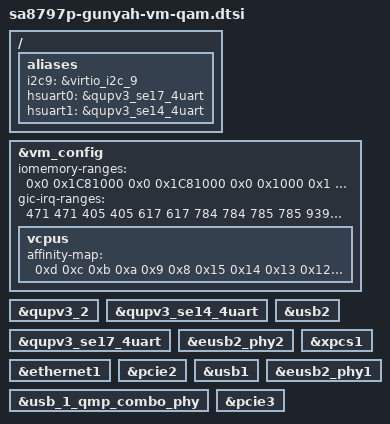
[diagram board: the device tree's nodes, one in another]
// SPDX-License-Identifier: BSD-3-Clause
/*
 * Copyright (c) Qualcomm Technologies, Inc. and/or its subsidiaries.
 */

#include "sa8797p-gunyah-vm.dtsi"
#include "sa8797p-gunyah-vm-qupv3.dtsi"
#include "sa8797p-vm-usb.dtsi"
#include "sa8797p-vm-pcie.dtsi"
#include "sa8797p-pinctrl.dtsi"

/ {
	aliases {
		i2c9 = &virtio_i2c_9;
		hsuart0 = &qupv3_se17_4uart;
		hsuart1 = &qupv3_se14_4uart;
	};
};

&vm_config {
	/* Pass through regions */
	iomemory-ranges = <
		/* TSC READ CNTCV region */
		0x0 0x1C81000 0x0 0x1C81000 0x0 0x1000 0x1
		/* MPROC NS1 IPCC region */
		0x0 0x9008000 0x0 0x9008000 0x0 0x1000 0x0
		/* QUPv3 Tile 2 read-only region */
		0x0 0x8C0000 0x0 0x8C0000 0x0 0x2000 0x1
		/* QUPv3 SE14 region */
		0x0 0x880000 0x0 0x880000 0x0 0x3000 0x0
		/* QUPv3 SE17 region */
		0x0 0x88C000 0x0 0x88C000 0x0 0x3000 0x0
		/* USB2 region */
		0x0 0x88e0000 0x0 0x88e0000 0x0 0x1000 0x0
		0x0 0xa200000 0x0 0xa200000 0x0 0x200000 0x0
		/* PCIE2 regions */
		0x40 0x0 0x40 0x0 0x0 0x10000000 0x0
		0x0 0x50000000 0x0 0x50000000 0x0 0x100000 0x0
		0x0 0x50100000 0x0 0x50100000 0x0 0x7000000 0x0
		0x40 0x10100000 0x40 0x10100000 0x0 0x100000 0x0
		/* TLMM region */
		0x0 0xF000000 0x0 0xF000000 0x0 0x1000000 0x0
		/* MDSS 0 region */
		0x0 0xAE00000 0x0 0xAE00000 0x0 0x180000 0x1
		/* MDSS 0 LUT DMA CTL region */
		0x0 0x0AF80000 0x0 0x0AF80000 0x0 0x1000 0x1
		/* MDSS 0 LUT DMA VQ region */
		0x0 0x0AF81000 0x0 0x0AF81000 0x0 0x10000 0x0
		/* MDSS 0 VA_TRAN CTL region */
		0x0 0xAFA4000 0x0 0xAFA4000 0x0 0x1000 0x1
		/* MDSS 0 VA_TRAN VQ region */
		0x0 0xAFA5000 0x0 0xAFA5000 0x0 0x10000 0x0
		/* MDSS 1 region */
		0x0 0x8C00000 0x0 0x8C00000 0x0 0x180000 0x1
		/* MDSS 1 LUT DMA CTL region */
		0x0 0x8D80000 0x0 0x8D80000 0x0 0x1000 0x1
		/* MDSS 1 LUT DMA VQ region */
		0x0 0x8D81000 0x0 0x8D81000 0x0 0x10000 0x0
		/* MDSS 1 VA_TRAN CTL region */
		0x0 0x8DA4000 0x0 0x8DA4000 0x0 0x1000 0x1
		/* MDSS 1 VA_TRAN VQ region */
		0x0 0x8DA5000 0x0 0x8DA5000 0x0 0x10000 0x0
		/* QRNG region */
		0x0 0x10cd000 0x0 0x10cd000 0x0 0x1000 0x0
		/* EMAC 1 DWC region */
		0x0 0x1A80000 0x0 0x1A80000 0x0 0x1A000 0x0
		/* EMAC 1 IO CSR region */
		0x0 0x1AFF000 0x0 0x1AFF000 0x0 0x1000 0x0
		/* GPU_0_GMU region */
		0x0 0x3D40000 0x0 0x3D40000 0x0 0x1000 0x0
		/* GPU_1_GMU region */
		0x0 0x9840000 0x0 0x9840000 0x0 0x1000 0x0
		/* PDC region */
		0x0 0xb220000 0x0 0xb220000 0x0 0x10000 0x0
		/* VCODEC CS1 region */
		0x0 0xAAA1000 0x0 0xAAA1000 0x0 0x1000 0x0
		/* USB1 region */
		0x0 0x88eb000 0x0 0x88eb000 0x0 0x1000 0x0
		0x0 0x88e4000 0x0 0x88e4000 0x0 0x3000 0x0
		0x0 0xa400000 0x0 0xa400000 0x0 0x200000 0x0
		/* PCIE3 regions */
		0x4 0x0 0x4 0x0 0x0 0x10000000 0x0
		0x0 0x58000000 0x0 0x58000000 0x0 0x100000 0x0
		0x0 0x58100000 0x0 0x58100000 0x0 0x7000000 0x0
		0x4 0x10100000 0x4 0x10100000 0x0 0x100000 0x0
		/* Fence NS1 IPCC region */
		0x0 0x9307000 0x0 0x9307000 0x0 0x1000 0x0
		/* Board serial number region */
		0x0 0x360D4000 0x0 0x360D4000 0x0 0x1000 0x1
	>;

	/* Pass through IRQs */
	gic-irq-ranges = <
		/* MPROC NS1 IPCC GIC IRQ */
		471 471
		/* QUPv3 SE14 GIC IRQ */
		405 405
		/* QUPv3 SE17 GIC IRQ */
		617 617
		/*USB2 IRQs*/
		784 784
		785 785
		939 939
		942 942
		/* PCIE2 GIC IRQs */
		876 876
		870 870
		145 145
		857 857
		878 878
		382 382
		869 869
		136 136
		/* EMAC 1 */
		852 852
		535 535
		775 775
		776 776
		761 761
		762 762
		763 763
		764 764
		765 765
		766 766
		767 767
		768 768
		734 734
		688 688
		393 393
		/* GPU 0 GMU */
		676 676
		/* GPU 1 GMU */
		893 893
		/* VCODEC CS1 */
		214 214
		/* USB1 IRQs */
		789 789
		790 790
		818 818
		949 949
		950 950
		/* PCIE3 GIC IRQs */
		396 396
		319 319
		863 863
		691 691
		872 872
		855 855
		273 273
		272 272
		/* Fence NS1 IPCC GIC IRQ */
		491 491
	>;

	vcpus {
		affinity-map = <0xd 0xc 0xb 0xa 0x9 0x8 0x15 0x14 0x13 0x12 0x11 0x10 0x5 0x4 0x3 0x2>;
	};
};

&qupv3_2 {
	status = "ok";
};

&qupv3_se14_4uart {
	status = "ok";
};

&qupv3_se17_4uart {
	status = "ok";
};

&usb2 {
	status = "ok";
};

&eusb2_phy2 {
	status = "ok";
};

&xpcs1 {
	status = "okay";
};

&ethernet1 {
	status = "okay";
};

&pcie2 {
	status = "ok";
};

&usb1 {
	status = "ok";
};

&eusb2_phy1 {
	status = "ok";
};

&usb_1_qmp_combo_phy {
	status = "ok";
};

&pcie3 {
	status = "ok";
};
